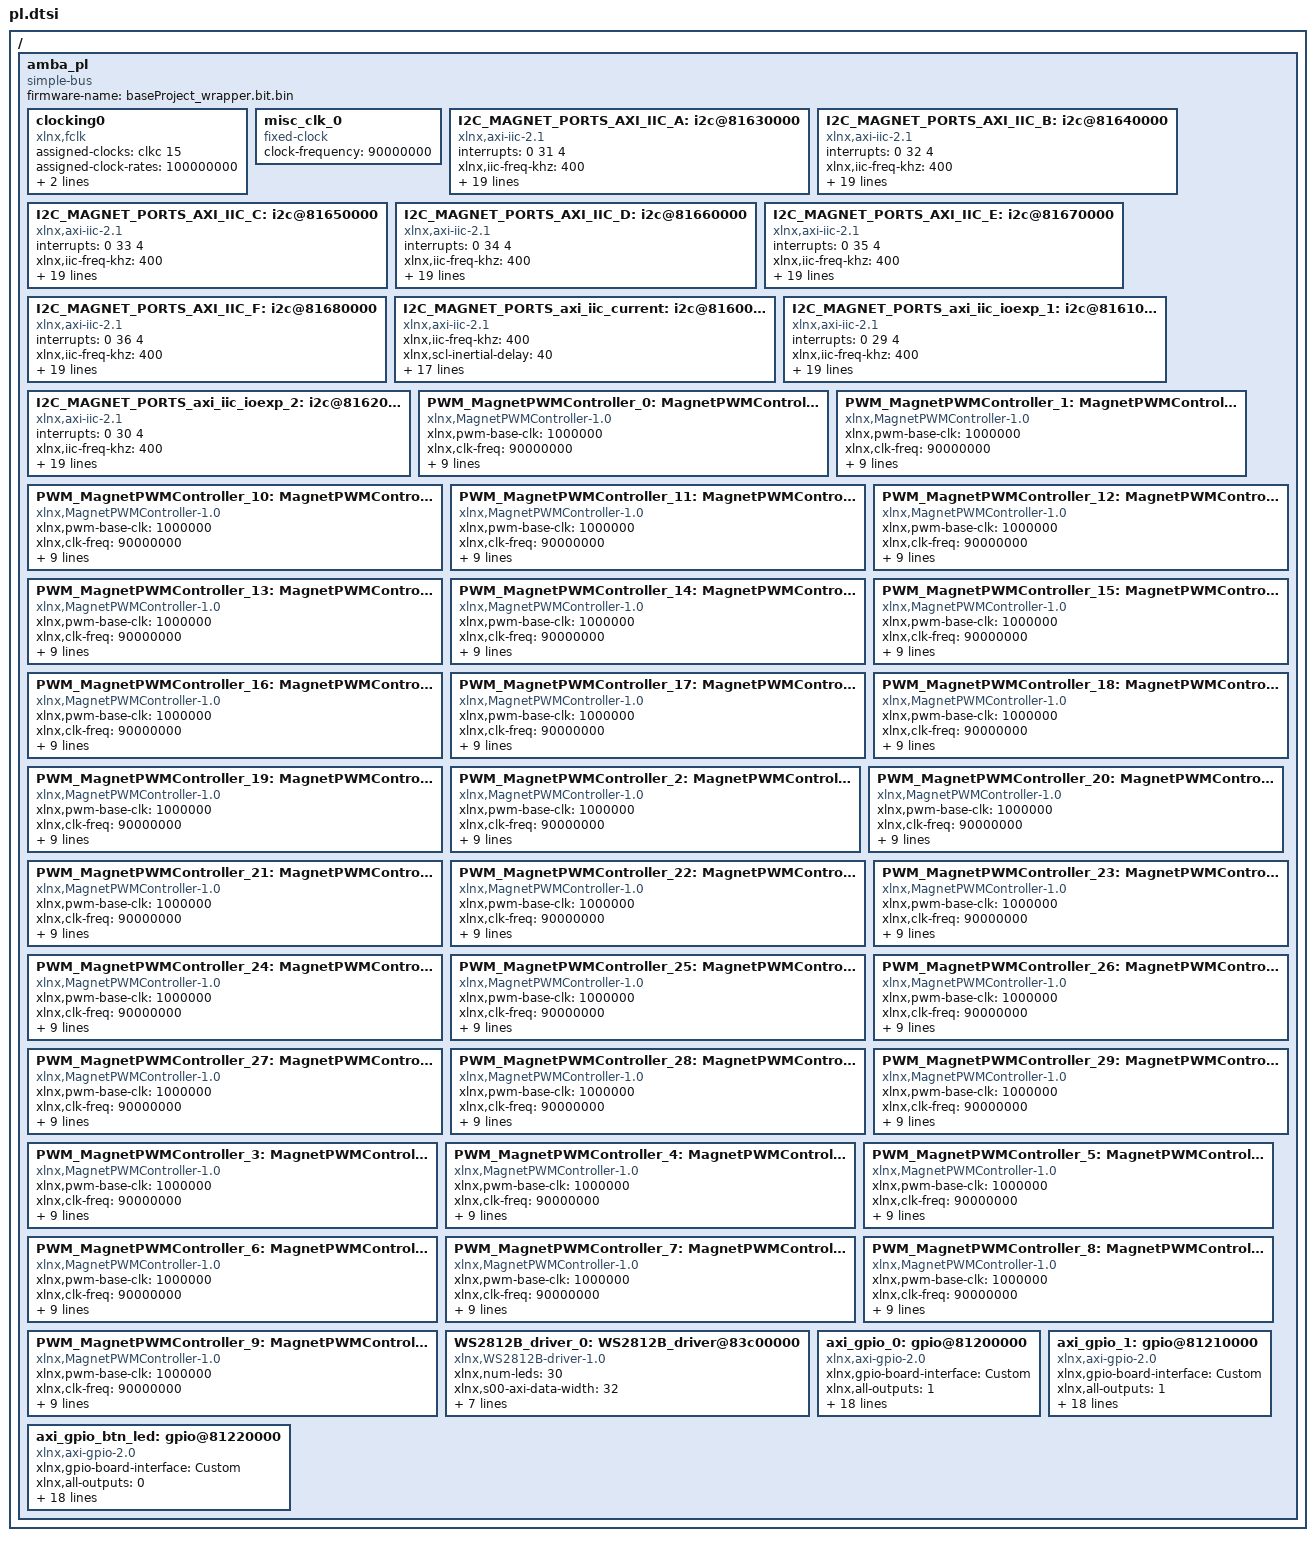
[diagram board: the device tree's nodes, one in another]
/ {
	amba_pl: amba_pl {
		ranges;
		compatible = "simple-bus";
		#address-cells = <1>;
		#size-cells = <1>;
		firmware-name = "baseProject_wrapper.bit.bin";
		clocking0: clocking0 {
			compatible = "xlnx,fclk";
			assigned-clocks = <&clkc 15>;
			assigned-clock-rates = <100000000>;
			#clock-cells = <0>;
			clock-output-names = "fabric_clk";
			clocks = <&clkc 15>;
		};
		misc_clk_0: misc_clk_0 {
			compatible = "fixed-clock";
			clock-frequency = <90000000>;
			#clock-cells = <0>;
		};
		I2C_MAGNET_PORTS_AXI_IIC_A: i2c@81630000 {
			interrupts = < 0 31 4 >;
			xlnx,iic-freq-khz = <400>;
			compatible = "xlnx,axi-iic-2.1" , "xlnx,xps-iic-2.00.a";
			xlnx,scl-inertial-delay = <40>;
			interrupt-parent = <&intc>;
			xlnx,ip-name = "axi_iic";
			xlnx,disable-setup-violation-check = <0>;
			reg = <0x81630000 0x10000>;
			clocks = <&misc_clk_0>;
			xlnx,gpo-width = <1>;
			xlnx,edk-iptype = "PERIPHERAL";
			xlnx,static-timing-reg-width = <0>;
			xlnx,sda-level = <1>;
			status = "okay";
			clock-names = "s_axi_aclk";
			xlnx,ten-bit-adr = <0>;
			xlnx,default-value = <0x0>;
			interrupt-names = "iic2intc_irpt";
			xlnx,iic-board-interface = "Custom";
			xlnx,timing-reg-width = <32>;
			xlnx,iic-freq = <400000>;
			xlnx,smbus-pmbus-host = <0>;
			xlnx,name = "I2C_MAGNET_PORTS_AXI_IIC_A";
			xlnx,axi-aclk-freq-mhz = <90>;
			xlnx,sda-inertial-delay = <40>;
		};
		I2C_MAGNET_PORTS_AXI_IIC_B: i2c@81640000 {
			interrupts = < 0 32 4 >;
			xlnx,iic-freq-khz = <400>;
			compatible = "xlnx,axi-iic-2.1" , "xlnx,xps-iic-2.00.a";
			xlnx,scl-inertial-delay = <40>;
			interrupt-parent = <&intc>;
			xlnx,ip-name = "axi_iic";
			xlnx,disable-setup-violation-check = <0>;
			reg = <0x81640000 0x10000>;
			clocks = <&misc_clk_0>;
			xlnx,gpo-width = <1>;
			xlnx,edk-iptype = "PERIPHERAL";
			xlnx,static-timing-reg-width = <0>;
			xlnx,sda-level = <1>;
			status = "okay";
			clock-names = "s_axi_aclk";
			xlnx,ten-bit-adr = <0>;
			xlnx,default-value = <0x0>;
			interrupt-names = "iic2intc_irpt";
			xlnx,iic-board-interface = "Custom";
			xlnx,timing-reg-width = <32>;
			xlnx,iic-freq = <400000>;
			xlnx,smbus-pmbus-host = <0>;
			xlnx,name = "I2C_MAGNET_PORTS_AXI_IIC_B";
			xlnx,axi-aclk-freq-mhz = <90>;
			xlnx,sda-inertial-delay = <40>;
		};
		I2C_MAGNET_PORTS_AXI_IIC_C: i2c@81650000 {
			interrupts = < 0 33 4 >;
			xlnx,iic-freq-khz = <400>;
			compatible = "xlnx,axi-iic-2.1" , "xlnx,xps-iic-2.00.a";
			xlnx,scl-inertial-delay = <40>;
			interrupt-parent = <&intc>;
			xlnx,ip-name = "axi_iic";
			xlnx,disable-setup-violation-check = <0>;
			reg = <0x81650000 0x10000>;
			clocks = <&misc_clk_0>;
			xlnx,gpo-width = <1>;
			xlnx,edk-iptype = "PERIPHERAL";
			xlnx,static-timing-reg-width = <0>;
			xlnx,sda-level = <1>;
			status = "okay";
			clock-names = "s_axi_aclk";
			xlnx,ten-bit-adr = <0>;
			xlnx,default-value = <0x0>;
			interrupt-names = "iic2intc_irpt";
			xlnx,iic-board-interface = "Custom";
			xlnx,timing-reg-width = <32>;
			xlnx,iic-freq = <400000>;
			xlnx,smbus-pmbus-host = <0>;
			xlnx,name = "I2C_MAGNET_PORTS_AXI_IIC_C";
			xlnx,axi-aclk-freq-mhz = <90>;
			xlnx,sda-inertial-delay = <40>;
		};
		I2C_MAGNET_PORTS_AXI_IIC_D: i2c@81660000 {
			interrupts = < 0 34 4 >;
			xlnx,iic-freq-khz = <400>;
			compatible = "xlnx,axi-iic-2.1" , "xlnx,xps-iic-2.00.a";
			xlnx,scl-inertial-delay = <40>;
			interrupt-parent = <&intc>;
			xlnx,ip-name = "axi_iic";
			xlnx,disable-setup-violation-check = <0>;
			reg = <0x81660000 0x10000>;
			clocks = <&misc_clk_0>;
			xlnx,gpo-width = <1>;
			xlnx,edk-iptype = "PERIPHERAL";
			xlnx,static-timing-reg-width = <0>;
			xlnx,sda-level = <1>;
			status = "okay";
			clock-names = "s_axi_aclk";
			xlnx,ten-bit-adr = <0>;
			xlnx,default-value = <0x0>;
			interrupt-names = "iic2intc_irpt";
			xlnx,iic-board-interface = "Custom";
			xlnx,timing-reg-width = <32>;
			xlnx,iic-freq = <400000>;
			xlnx,smbus-pmbus-host = <0>;
			xlnx,name = "I2C_MAGNET_PORTS_AXI_IIC_D";
			xlnx,axi-aclk-freq-mhz = <90>;
			xlnx,sda-inertial-delay = <40>;
		};
		I2C_MAGNET_PORTS_AXI_IIC_E: i2c@81670000 {
			interrupts = < 0 35 4 >;
			xlnx,iic-freq-khz = <400>;
			compatible = "xlnx,axi-iic-2.1" , "xlnx,xps-iic-2.00.a";
			xlnx,scl-inertial-delay = <40>;
			interrupt-parent = <&intc>;
			xlnx,ip-name = "axi_iic";
			xlnx,disable-setup-violation-check = <0>;
			reg = <0x81670000 0x10000>;
			clocks = <&misc_clk_0>;
			xlnx,gpo-width = <1>;
			xlnx,edk-iptype = "PERIPHERAL";
			xlnx,static-timing-reg-width = <0>;
			xlnx,sda-level = <1>;
			status = "okay";
			clock-names = "s_axi_aclk";
			xlnx,ten-bit-adr = <0>;
			xlnx,default-value = <0x0>;
			interrupt-names = "iic2intc_irpt";
			xlnx,iic-board-interface = "Custom";
			xlnx,timing-reg-width = <32>;
			xlnx,iic-freq = <400000>;
			xlnx,smbus-pmbus-host = <0>;
			xlnx,name = "I2C_MAGNET_PORTS_AXI_IIC_E";
			xlnx,axi-aclk-freq-mhz = <90>;
			xlnx,sda-inertial-delay = <40>;
		};
		I2C_MAGNET_PORTS_AXI_IIC_F: i2c@81680000 {
			interrupts = < 0 36 4 >;
			xlnx,iic-freq-khz = <400>;
			compatible = "xlnx,axi-iic-2.1" , "xlnx,xps-iic-2.00.a";
			xlnx,scl-inertial-delay = <40>;
			interrupt-parent = <&intc>;
			xlnx,ip-name = "axi_iic";
			xlnx,disable-setup-violation-check = <0>;
			reg = <0x81680000 0x10000>;
			clocks = <&misc_clk_0>;
			xlnx,gpo-width = <1>;
			xlnx,edk-iptype = "PERIPHERAL";
			xlnx,static-timing-reg-width = <0>;
			xlnx,sda-level = <1>;
			status = "okay";
			clock-names = "s_axi_aclk";
			xlnx,ten-bit-adr = <0>;
			xlnx,default-value = <0x0>;
			interrupt-names = "iic2intc_irpt";
			xlnx,iic-board-interface = "Custom";
			xlnx,timing-reg-width = <32>;
			xlnx,iic-freq = <400000>;
			xlnx,smbus-pmbus-host = <0>;
			xlnx,name = "I2C_MAGNET_PORTS_AXI_IIC_F";
			xlnx,axi-aclk-freq-mhz = <90>;
			xlnx,sda-inertial-delay = <40>;
		};
		I2C_MAGNET_PORTS_axi_iic_current: i2c@81600000 {
			xlnx,iic-freq-khz = <400>;
			compatible = "xlnx,axi-iic-2.1" , "xlnx,xps-iic-2.00.a";
			xlnx,scl-inertial-delay = <40>;
			xlnx,ip-name = "axi_iic";
			xlnx,disable-setup-violation-check = <0>;
			reg = <0x81600000 0x10000>;
			clocks = <&misc_clk_0>;
			xlnx,gpo-width = <1>;
			xlnx,edk-iptype = "PERIPHERAL";
			xlnx,static-timing-reg-width = <0>;
			xlnx,sda-level = <1>;
			status = "okay";
			clock-names = "s_axi_aclk";
			xlnx,ten-bit-adr = <0>;
			xlnx,default-value = <0x0>;
			xlnx,iic-board-interface = "Custom";
			xlnx,timing-reg-width = <32>;
			xlnx,iic-freq = <400000>;
			xlnx,smbus-pmbus-host = <0>;
			xlnx,name = "I2C_MAGNET_PORTS_axi_iic_current";
			xlnx,axi-aclk-freq-mhz = <90>;
			xlnx,sda-inertial-delay = <40>;
		};
		I2C_MAGNET_PORTS_axi_iic_ioexp_1: i2c@81610000 {
			interrupts = < 0 29 4 >;
			xlnx,iic-freq-khz = <400>;
			compatible = "xlnx,axi-iic-2.1" , "xlnx,xps-iic-2.00.a";
			xlnx,scl-inertial-delay = <40>;
			interrupt-parent = <&intc>;
			xlnx,ip-name = "axi_iic";
			xlnx,disable-setup-violation-check = <0>;
			reg = <0x81610000 0x10000>;
			clocks = <&misc_clk_0>;
			xlnx,gpo-width = <1>;
			xlnx,edk-iptype = "PERIPHERAL";
			xlnx,static-timing-reg-width = <0>;
			xlnx,sda-level = <1>;
			status = "okay";
			clock-names = "s_axi_aclk";
			xlnx,ten-bit-adr = <0>;
			xlnx,default-value = <0x0>;
			interrupt-names = "iic2intc_irpt";
			xlnx,iic-board-interface = "Custom";
			xlnx,timing-reg-width = <32>;
			xlnx,iic-freq = <400000>;
			xlnx,smbus-pmbus-host = <0>;
			xlnx,name = "I2C_MAGNET_PORTS_axi_iic_ioexp_1";
			xlnx,axi-aclk-freq-mhz = <90>;
			xlnx,sda-inertial-delay = <40>;
		};
		I2C_MAGNET_PORTS_axi_iic_ioexp_2: i2c@81620000 {
			interrupts = < 0 30 4 >;
			xlnx,iic-freq-khz = <400>;
			compatible = "xlnx,axi-iic-2.1" , "xlnx,xps-iic-2.00.a";
			xlnx,scl-inertial-delay = <40>;
			interrupt-parent = <&intc>;
			xlnx,ip-name = "axi_iic";
			xlnx,disable-setup-violation-check = <0>;
			reg = <0x81620000 0x10000>;
			clocks = <&misc_clk_0>;
			xlnx,gpo-width = <1>;
			xlnx,edk-iptype = "PERIPHERAL";
			xlnx,static-timing-reg-width = <0>;
			xlnx,sda-level = <1>;
			status = "okay";
			clock-names = "s_axi_aclk";
			xlnx,ten-bit-adr = <0>;
			xlnx,default-value = <0x0>;
			interrupt-names = "iic2intc_irpt";
			xlnx,iic-board-interface = "Custom";
			xlnx,timing-reg-width = <32>;
			xlnx,iic-freq = <400000>;
			xlnx,smbus-pmbus-host = <0>;
			xlnx,name = "I2C_MAGNET_PORTS_axi_iic_ioexp_2";
			xlnx,axi-aclk-freq-mhz = <90>;
			xlnx,sda-inertial-delay = <40>;
		};
		PWM_MagnetPWMController_0: MagnetPWMController@43c00000 {
			compatible = "xlnx,MagnetPWMController-1.0";
			xlnx,pwm-base-clk = <1000000>;
			xlnx,clk-freq = <90000000>;
			xlnx,s00-axi-data-width = <32>;
			xlnx,temp-histeresis = <10>;
			xlnx,ip-name = "MagnetPWMController";
			reg = <0x43c00000 0x10000>;
			clocks = <&misc_clk_0>, <&misc_clk_0>;
			xlnx,temp-limit = <90>;
			xlnx,edk-iptype = "PERIPHERAL";
			status = "okay";
			clock-names = "PL_CLK" , "s00_axi_aclk";
			xlnx,s00-axi-addr-width = <6>;
			xlnx,name = "PWM_MagnetPWMController_0";
		};
		PWM_MagnetPWMController_1: MagnetPWMController@43c10000 {
			compatible = "xlnx,MagnetPWMController-1.0";
			xlnx,pwm-base-clk = <1000000>;
			xlnx,clk-freq = <90000000>;
			xlnx,s00-axi-data-width = <32>;
			xlnx,temp-histeresis = <10>;
			xlnx,ip-name = "MagnetPWMController";
			reg = <0x43c10000 0x10000>;
			clocks = <&misc_clk_0>, <&misc_clk_0>;
			xlnx,temp-limit = <90>;
			xlnx,edk-iptype = "PERIPHERAL";
			status = "okay";
			clock-names = "PL_CLK" , "s00_axi_aclk";
			xlnx,s00-axi-addr-width = <6>;
			xlnx,name = "PWM_MagnetPWMController_1";
		};
		PWM_MagnetPWMController_10: MagnetPWMController@43ca0000 {
			compatible = "xlnx,MagnetPWMController-1.0";
			xlnx,pwm-base-clk = <1000000>;
			xlnx,clk-freq = <90000000>;
			xlnx,s00-axi-data-width = <32>;
			xlnx,temp-histeresis = <10>;
			xlnx,ip-name = "MagnetPWMController";
			reg = <0x43ca0000 0x10000>;
			clocks = <&misc_clk_0>, <&misc_clk_0>;
			xlnx,temp-limit = <90>;
			xlnx,edk-iptype = "PERIPHERAL";
			status = "okay";
			clock-names = "PL_CLK" , "s00_axi_aclk";
			xlnx,s00-axi-addr-width = <6>;
			xlnx,name = "PWM_MagnetPWMController_10";
		};
		PWM_MagnetPWMController_11: MagnetPWMController@43cb0000 {
			compatible = "xlnx,MagnetPWMController-1.0";
			xlnx,pwm-base-clk = <1000000>;
			xlnx,clk-freq = <90000000>;
			xlnx,s00-axi-data-width = <32>;
			xlnx,temp-histeresis = <10>;
			xlnx,ip-name = "MagnetPWMController";
			reg = <0x43cb0000 0x10000>;
			clocks = <&misc_clk_0>, <&misc_clk_0>;
			xlnx,temp-limit = <90>;
			xlnx,edk-iptype = "PERIPHERAL";
			status = "okay";
			clock-names = "PL_CLK" , "s00_axi_aclk";
			xlnx,s00-axi-addr-width = <6>;
			xlnx,name = "PWM_MagnetPWMController_11";
		};
		PWM_MagnetPWMController_12: MagnetPWMController@43cc0000 {
			compatible = "xlnx,MagnetPWMController-1.0";
			xlnx,pwm-base-clk = <1000000>;
			xlnx,clk-freq = <90000000>;
			xlnx,s00-axi-data-width = <32>;
			xlnx,temp-histeresis = <10>;
			xlnx,ip-name = "MagnetPWMController";
			reg = <0x43cc0000 0x10000>;
			clocks = <&misc_clk_0>, <&misc_clk_0>;
			xlnx,temp-limit = <90>;
			xlnx,edk-iptype = "PERIPHERAL";
			status = "okay";
			clock-names = "PL_CLK" , "s00_axi_aclk";
			xlnx,s00-axi-addr-width = <6>;
			xlnx,name = "PWM_MagnetPWMController_12";
		};
		PWM_MagnetPWMController_13: MagnetPWMController@43cd0000 {
			compatible = "xlnx,MagnetPWMController-1.0";
			xlnx,pwm-base-clk = <1000000>;
			xlnx,clk-freq = <90000000>;
			xlnx,s00-axi-data-width = <32>;
			xlnx,temp-histeresis = <10>;
			xlnx,ip-name = "MagnetPWMController";
			reg = <0x43cd0000 0x10000>;
			clocks = <&misc_clk_0>, <&misc_clk_0>;
			xlnx,temp-limit = <90>;
			xlnx,edk-iptype = "PERIPHERAL";
			status = "okay";
			clock-names = "PL_CLK" , "s00_axi_aclk";
			xlnx,s00-axi-addr-width = <6>;
			xlnx,name = "PWM_MagnetPWMController_13";
		};
		PWM_MagnetPWMController_14: MagnetPWMController@43ce0000 {
			compatible = "xlnx,MagnetPWMController-1.0";
			xlnx,pwm-base-clk = <1000000>;
			xlnx,clk-freq = <90000000>;
			xlnx,s00-axi-data-width = <32>;
			xlnx,temp-histeresis = <10>;
			xlnx,ip-name = "MagnetPWMController";
			reg = <0x43ce0000 0x10000>;
			clocks = <&misc_clk_0>, <&misc_clk_0>;
			xlnx,temp-limit = <90>;
			xlnx,edk-iptype = "PERIPHERAL";
			status = "okay";
			clock-names = "PL_CLK" , "s00_axi_aclk";
			xlnx,s00-axi-addr-width = <6>;
			xlnx,name = "PWM_MagnetPWMController_14";
		};
		PWM_MagnetPWMController_15: MagnetPWMController@43cf0000 {
			compatible = "xlnx,MagnetPWMController-1.0";
			xlnx,pwm-base-clk = <1000000>;
			xlnx,clk-freq = <90000000>;
			xlnx,s00-axi-data-width = <32>;
			xlnx,temp-histeresis = <10>;
			xlnx,ip-name = "MagnetPWMController";
			reg = <0x43cf0000 0x10000>;
			clocks = <&misc_clk_0>, <&misc_clk_0>;
			xlnx,temp-limit = <90>;
			xlnx,edk-iptype = "PERIPHERAL";
			status = "okay";
			clock-names = "PL_CLK" , "s00_axi_aclk";
			xlnx,s00-axi-addr-width = <6>;
			xlnx,name = "PWM_MagnetPWMController_15";
		};
		PWM_MagnetPWMController_16: MagnetPWMController@43d00000 {
			compatible = "xlnx,MagnetPWMController-1.0";
			xlnx,pwm-base-clk = <1000000>;
			xlnx,clk-freq = <90000000>;
			xlnx,s00-axi-data-width = <32>;
			xlnx,temp-histeresis = <10>;
			xlnx,ip-name = "MagnetPWMController";
			reg = <0x43d00000 0x10000>;
			clocks = <&misc_clk_0>, <&misc_clk_0>;
			xlnx,temp-limit = <90>;
			xlnx,edk-iptype = "PERIPHERAL";
			status = "okay";
			clock-names = "PL_CLK" , "s00_axi_aclk";
			xlnx,s00-axi-addr-width = <6>;
			xlnx,name = "PWM_MagnetPWMController_16";
		};
		PWM_MagnetPWMController_17: MagnetPWMController@43d10000 {
			compatible = "xlnx,MagnetPWMController-1.0";
			xlnx,pwm-base-clk = <1000000>;
			xlnx,clk-freq = <90000000>;
			xlnx,s00-axi-data-width = <32>;
			xlnx,temp-histeresis = <10>;
			xlnx,ip-name = "MagnetPWMController";
			reg = <0x43d10000 0x10000>;
			clocks = <&misc_clk_0>, <&misc_clk_0>;
			xlnx,temp-limit = <90>;
			xlnx,edk-iptype = "PERIPHERAL";
			status = "okay";
			clock-names = "PL_CLK" , "s00_axi_aclk";
			xlnx,s00-axi-addr-width = <6>;
			xlnx,name = "PWM_MagnetPWMController_17";
		};
		PWM_MagnetPWMController_18: MagnetPWMController@43d20000 {
			compatible = "xlnx,MagnetPWMController-1.0";
			xlnx,pwm-base-clk = <1000000>;
			xlnx,clk-freq = <90000000>;
			xlnx,s00-axi-data-width = <32>;
			xlnx,temp-histeresis = <10>;
			xlnx,ip-name = "MagnetPWMController";
			reg = <0x43d20000 0x10000>;
			clocks = <&misc_clk_0>, <&misc_clk_0>;
			xlnx,temp-limit = <90>;
			xlnx,edk-iptype = "PERIPHERAL";
			status = "okay";
			clock-names = "PL_CLK" , "s00_axi_aclk";
			xlnx,s00-axi-addr-width = <6>;
			xlnx,name = "PWM_MagnetPWMController_18";
		};
		PWM_MagnetPWMController_19: MagnetPWMController@43d30000 {
			compatible = "xlnx,MagnetPWMController-1.0";
			xlnx,pwm-base-clk = <1000000>;
			xlnx,clk-freq = <90000000>;
			xlnx,s00-axi-data-width = <32>;
			xlnx,temp-histeresis = <10>;
			xlnx,ip-name = "MagnetPWMController";
			reg = <0x43d30000 0x10000>;
			clocks = <&misc_clk_0>, <&misc_clk_0>;
			xlnx,temp-limit = <90>;
			xlnx,edk-iptype = "PERIPHERAL";
			status = "okay";
			clock-names = "PL_CLK" , "s00_axi_aclk";
			xlnx,s00-axi-addr-width = <6>;
			xlnx,name = "PWM_MagnetPWMController_19";
		};
		PWM_MagnetPWMController_2: MagnetPWMController@43c20000 {
			compatible = "xlnx,MagnetPWMController-1.0";
			xlnx,pwm-base-clk = <1000000>;
			xlnx,clk-freq = <90000000>;
			xlnx,s00-axi-data-width = <32>;
			xlnx,temp-histeresis = <10>;
			xlnx,ip-name = "MagnetPWMController";
			reg = <0x43c20000 0x10000>;
			clocks = <&misc_clk_0>, <&misc_clk_0>;
			xlnx,temp-limit = <90>;
			xlnx,edk-iptype = "PERIPHERAL";
			status = "okay";
			clock-names = "PL_CLK" , "s00_axi_aclk";
			xlnx,s00-axi-addr-width = <6>;
			xlnx,name = "PWM_MagnetPWMController_2";
		};
		PWM_MagnetPWMController_20: MagnetPWMController@43d40000 {
			compatible = "xlnx,MagnetPWMController-1.0";
			xlnx,pwm-base-clk = <1000000>;
			xlnx,clk-freq = <90000000>;
			xlnx,s00-axi-data-width = <32>;
			xlnx,temp-histeresis = <10>;
			xlnx,ip-name = "MagnetPWMController";
			reg = <0x43d40000 0x10000>;
			clocks = <&misc_clk_0>, <&misc_clk_0>;
			xlnx,temp-limit = <90>;
			xlnx,edk-iptype = "PERIPHERAL";
			status = "okay";
			clock-names = "PL_CLK" , "s00_axi_aclk";
			xlnx,s00-axi-addr-width = <6>;
			xlnx,name = "PWM_MagnetPWMController_20";
		};
		PWM_MagnetPWMController_21: MagnetPWMController@43d50000 {
			compatible = "xlnx,MagnetPWMController-1.0";
			xlnx,pwm-base-clk = <1000000>;
			xlnx,clk-freq = <90000000>;
			xlnx,s00-axi-data-width = <32>;
			xlnx,temp-histeresis = <10>;
			xlnx,ip-name = "MagnetPWMController";
			reg = <0x43d50000 0x10000>;
			clocks = <&misc_clk_0>, <&misc_clk_0>;
			xlnx,temp-limit = <90>;
			xlnx,edk-iptype = "PERIPHERAL";
			status = "okay";
			clock-names = "PL_CLK" , "s00_axi_aclk";
			xlnx,s00-axi-addr-width = <6>;
			xlnx,name = "PWM_MagnetPWMController_21";
		};
		PWM_MagnetPWMController_22: MagnetPWMController@43d60000 {
			compatible = "xlnx,MagnetPWMController-1.0";
			xlnx,pwm-base-clk = <1000000>;
			xlnx,clk-freq = <90000000>;
			xlnx,s00-axi-data-width = <32>;
			xlnx,temp-histeresis = <10>;
			xlnx,ip-name = "MagnetPWMController";
			reg = <0x43d60000 0x10000>;
			clocks = <&misc_clk_0>, <&misc_clk_0>;
			xlnx,temp-limit = <90>;
			xlnx,edk-iptype = "PERIPHERAL";
			status = "okay";
			clock-names = "PL_CLK" , "s00_axi_aclk";
			xlnx,s00-axi-addr-width = <6>;
			xlnx,name = "PWM_MagnetPWMController_22";
		};
		PWM_MagnetPWMController_23: MagnetPWMController@43d70000 {
			compatible = "xlnx,MagnetPWMController-1.0";
			xlnx,pwm-base-clk = <1000000>;
			xlnx,clk-freq = <90000000>;
			xlnx,s00-axi-data-width = <32>;
			xlnx,temp-histeresis = <10>;
			xlnx,ip-name = "MagnetPWMController";
			reg = <0x43d70000 0x10000>;
			clocks = <&misc_clk_0>, <&misc_clk_0>;
			xlnx,temp-limit = <90>;
			xlnx,edk-iptype = "PERIPHERAL";
			status = "okay";
			clock-names = "PL_CLK" , "s00_axi_aclk";
			xlnx,s00-axi-addr-width = <6>;
			xlnx,name = "PWM_MagnetPWMController_23";
		};
		PWM_MagnetPWMController_24: MagnetPWMController@43d80000 {
			compatible = "xlnx,MagnetPWMController-1.0";
			xlnx,pwm-base-clk = <1000000>;
			xlnx,clk-freq = <90000000>;
			xlnx,s00-axi-data-width = <32>;
			xlnx,temp-histeresis = <10>;
			xlnx,ip-name = "MagnetPWMController";
			reg = <0x43d80000 0x10000>;
			clocks = <&misc_clk_0>, <&misc_clk_0>;
			xlnx,temp-limit = <90>;
			xlnx,edk-iptype = "PERIPHERAL";
			status = "okay";
			clock-names = "PL_CLK" , "s00_axi_aclk";
			xlnx,s00-axi-addr-width = <6>;
			xlnx,name = "PWM_MagnetPWMController_24";
		};
		PWM_MagnetPWMController_25: MagnetPWMController@43d90000 {
			compatible = "xlnx,MagnetPWMController-1.0";
			xlnx,pwm-base-clk = <1000000>;
			xlnx,clk-freq = <90000000>;
			xlnx,s00-axi-data-width = <32>;
			xlnx,temp-histeresis = <10>;
			xlnx,ip-name = "MagnetPWMController";
			reg = <0x43d90000 0x10000>;
			clocks = <&misc_clk_0>, <&misc_clk_0>;
			xlnx,temp-limit = <90>;
			xlnx,edk-iptype = "PERIPHERAL";
			status = "okay";
			clock-names = "PL_CLK" , "s00_axi_aclk";
			xlnx,s00-axi-addr-width = <6>;
			xlnx,name = "PWM_MagnetPWMController_25";
		};
		PWM_MagnetPWMController_26: MagnetPWMController@43da0000 {
			compatible = "xlnx,MagnetPWMController-1.0";
			xlnx,pwm-base-clk = <1000000>;
			xlnx,clk-freq = <90000000>;
			xlnx,s00-axi-data-width = <32>;
			xlnx,temp-histeresis = <10>;
			xlnx,ip-name = "MagnetPWMController";
			reg = <0x43da0000 0x10000>;
			clocks = <&misc_clk_0>, <&misc_clk_0>;
			xlnx,temp-limit = <90>;
			xlnx,edk-iptype = "PERIPHERAL";
			status = "okay";
			clock-names = "PL_CLK" , "s00_axi_aclk";
			xlnx,s00-axi-addr-width = <6>;
			xlnx,name = "PWM_MagnetPWMController_26";
		};
		PWM_MagnetPWMController_27: MagnetPWMController@43db0000 {
			compatible = "xlnx,MagnetPWMController-1.0";
			xlnx,pwm-base-clk = <1000000>;
			xlnx,clk-freq = <90000000>;
			xlnx,s00-axi-data-width = <32>;
			xlnx,temp-histeresis = <10>;
			xlnx,ip-name = "MagnetPWMController";
			reg = <0x43db0000 0x10000>;
			clocks = <&misc_clk_0>, <&misc_clk_0>;
			xlnx,temp-limit = <90>;
			xlnx,edk-iptype = "PERIPHERAL";
			status = "okay";
			clock-names = "PL_CLK" , "s00_axi_aclk";
			xlnx,s00-axi-addr-width = <6>;
			xlnx,name = "PWM_MagnetPWMController_27";
		};
		PWM_MagnetPWMController_28: MagnetPWMController@43dc0000 {
			compatible = "xlnx,MagnetPWMController-1.0";
			xlnx,pwm-base-clk = <1000000>;
			xlnx,clk-freq = <90000000>;
			xlnx,s00-axi-data-width = <32>;
			xlnx,temp-histeresis = <10>;
			xlnx,ip-name = "MagnetPWMController";
			reg = <0x43dc0000 0x10000>;
			clocks = <&misc_clk_0>, <&misc_clk_0>;
			xlnx,temp-limit = <90>;
			xlnx,edk-iptype = "PERIPHERAL";
			status = "okay";
			clock-names = "PL_CLK" , "s00_axi_aclk";
			xlnx,s00-axi-addr-width = <6>;
			xlnx,name = "PWM_MagnetPWMController_28";
		};
		PWM_MagnetPWMController_29: MagnetPWMController@43dd0000 {
			compatible = "xlnx,MagnetPWMController-1.0";
			xlnx,pwm-base-clk = <1000000>;
			xlnx,clk-freq = <90000000>;
			xlnx,s00-axi-data-width = <32>;
			xlnx,temp-histeresis = <10>;
			xlnx,ip-name = "MagnetPWMController";
			reg = <0x43dd0000 0x10000>;
			clocks = <&misc_clk_0>, <&misc_clk_0>;
			xlnx,temp-limit = <90>;
			xlnx,edk-iptype = "PERIPHERAL";
			status = "okay";
			clock-names = "PL_CLK" , "s00_axi_aclk";
			xlnx,s00-axi-addr-width = <6>;
			xlnx,name = "PWM_MagnetPWMController_29";
		};
		PWM_MagnetPWMController_3: MagnetPWMController@43c30000 {
			compatible = "xlnx,MagnetPWMController-1.0";
			xlnx,pwm-base-clk = <1000000>;
			xlnx,clk-freq = <90000000>;
			xlnx,s00-axi-data-width = <32>;
			xlnx,temp-histeresis = <10>;
			xlnx,ip-name = "MagnetPWMController";
			reg = <0x43c30000 0x10000>;
			clocks = <&misc_clk_0>, <&misc_clk_0>;
			xlnx,temp-limit = <90>;
			xlnx,edk-iptype = "PERIPHERAL";
			status = "okay";
			clock-names = "PL_CLK" , "s00_axi_aclk";
			xlnx,s00-axi-addr-width = <6>;
			xlnx,name = "PWM_MagnetPWMController_3";
		};
		PWM_MagnetPWMController_4: MagnetPWMController@43c40000 {
			compatible = "xlnx,MagnetPWMController-1.0";
			xlnx,pwm-base-clk = <1000000>;
			xlnx,clk-freq = <90000000>;
			xlnx,s00-axi-data-width = <32>;
			xlnx,temp-histeresis = <10>;
			xlnx,ip-name = "MagnetPWMController";
			reg = <0x43c40000 0x10000>;
			clocks = <&misc_clk_0>, <&misc_clk_0>;
			xlnx,temp-limit = <90>;
			xlnx,edk-iptype = "PERIPHERAL";
			status = "okay";
			clock-names = "PL_CLK" , "s00_axi_aclk";
			xlnx,s00-axi-addr-width = <6>;
			xlnx,name = "PWM_MagnetPWMController_4";
		};
		PWM_MagnetPWMController_5: MagnetPWMController@43c50000 {
			compatible = "xlnx,MagnetPWMController-1.0";
			xlnx,pwm-base-clk = <1000000>;
			xlnx,clk-freq = <90000000>;
			xlnx,s00-axi-data-width = <32>;
			xlnx,temp-histeresis = <10>;
			xlnx,ip-name = "MagnetPWMController";
			reg = <0x43c50000 0x10000>;
			clocks = <&misc_clk_0>, <&misc_clk_0>;
			xlnx,temp-limit = <90>;
			xlnx,edk-iptype = "PERIPHERAL";
			status = "okay";
			clock-names = "PL_CLK" , "s00_axi_aclk";
			xlnx,s00-axi-addr-width = <6>;
			xlnx,name = "PWM_MagnetPWMController_5";
		};
		PWM_MagnetPWMController_6: MagnetPWMController@43c60000 {
			compatible = "xlnx,MagnetPWMController-1.0";
			xlnx,pwm-base-clk = <1000000>;
			xlnx,clk-freq = <90000000>;
			xlnx,s00-axi-data-width = <32>;
			xlnx,temp-histeresis = <10>;
			xlnx,ip-name = "MagnetPWMController";
			reg = <0x43c60000 0x10000>;
			clocks = <&misc_clk_0>, <&misc_clk_0>;
			xlnx,temp-limit = <90>;
			xlnx,edk-iptype = "PERIPHERAL";
			status = "okay";
			clock-names = "PL_CLK" , "s00_axi_aclk";
			xlnx,s00-axi-addr-width = <6>;
			xlnx,name = "PWM_MagnetPWMController_6";
		};
		PWM_MagnetPWMController_7: MagnetPWMController@43c70000 {
			compatible = "xlnx,MagnetPWMController-1.0";
			xlnx,pwm-base-clk = <1000000>;
			xlnx,clk-freq = <90000000>;
			xlnx,s00-axi-data-width = <32>;
			xlnx,temp-histeresis = <10>;
			xlnx,ip-name = "MagnetPWMController";
			reg = <0x43c70000 0x10000>;
			clocks = <&misc_clk_0>, <&misc_clk_0>;
			xlnx,temp-limit = <90>;
			xlnx,edk-iptype = "PERIPHERAL";
			status = "okay";
			clock-names = "PL_CLK" , "s00_axi_aclk";
			xlnx,s00-axi-addr-width = <6>;
			xlnx,name = "PWM_MagnetPWMController_7";
		};
		PWM_MagnetPWMController_8: MagnetPWMController@43c80000 {
			compatible = "xlnx,MagnetPWMController-1.0";
			xlnx,pwm-base-clk = <1000000>;
			xlnx,clk-freq = <90000000>;
			xlnx,s00-axi-data-width = <32>;
			xlnx,temp-histeresis = <10>;
			xlnx,ip-name = "MagnetPWMController";
			reg = <0x43c80000 0x10000>;
			clocks = <&misc_clk_0>, <&misc_clk_0>;
			xlnx,temp-limit = <90>;
			xlnx,edk-iptype = "PERIPHERAL";
			status = "okay";
			clock-names = "PL_CLK" , "s00_axi_aclk";
			xlnx,s00-axi-addr-width = <6>;
			xlnx,name = "PWM_MagnetPWMController_8";
		};
		PWM_MagnetPWMController_9: MagnetPWMController@43c90000 {
			compatible = "xlnx,MagnetPWMController-1.0";
			xlnx,pwm-base-clk = <1000000>;
			xlnx,clk-freq = <90000000>;
			xlnx,s00-axi-data-width = <32>;
			xlnx,temp-histeresis = <10>;
			xlnx,ip-name = "MagnetPWMController";
			reg = <0x43c90000 0x10000>;
			clocks = <&misc_clk_0>, <&misc_clk_0>;
			xlnx,temp-limit = <90>;
			xlnx,edk-iptype = "PERIPHERAL";
			status = "okay";
			clock-names = "PL_CLK" , "s00_axi_aclk";
			xlnx,s00-axi-addr-width = <6>;
			xlnx,name = "PWM_MagnetPWMController_9";
		};
		WS2812B_driver_0: WS2812B_driver@83c00000 {
			compatible = "xlnx,WS2812B-driver-1.0";
			xlnx,num-leds = <30>;
			xlnx,s00-axi-data-width = <32>;
			xlnx,ip-name = "WS2812B_driver";
			reg = <0x83c00000 0x10000>;
			clocks = <&misc_clk_0>, <&misc_clk_0>;
			xlnx,edk-iptype = "PERIPHERAL";
			status = "okay";
			xlnx,system-clock = <90000000>;
			xlnx,s00-axi-addr-width = <4>;
			clock-names = "s00_axi_aclk" , "sys_clk";
			xlnx,name = "WS2812B_driver_0";
		};
		axi_gpio_0: gpio@81200000 {
			xlnx,gpio-board-interface = "Custom";
			compatible = "xlnx,axi-gpio-2.0" , "xlnx,xps-gpio-1.00.a";
			xlnx,all-outputs = <1>;
			#gpio-cells = <2>;
			xlnx,gpio-width = <1>;
			xlnx,dout-default = <0x0>;
			xlnx,is-dual = <0>;
			xlnx,ip-name = "axi_gpio";
			xlnx,tri-default-2 = <0xffffffff>;
			reg = <0x81200000 0x10000>;
			xlnx,all-inputs-2 = <0>;
			clocks = <&misc_clk_0>;
			xlnx,all-outputs-2 = <0>;
			gpio-controller;
			xlnx,interrupt-present = <0>;
			xlnx,gpio2-board-interface = "Custom";
			xlnx,edk-iptype = "PERIPHERAL";
			xlnx,dout-default-2 = <0x0>;
			status = "okay";
			xlnx,gpio2-width = <32>;
			clock-names = "s_axi_aclk";
			xlnx,tri-default = <0xffffffff>;
			xlnx,name = "axi_gpio_0";
			xlnx,all-inputs = <0>;
		};
		axi_gpio_1: gpio@81210000 {
			xlnx,gpio-board-interface = "Custom";
			compatible = "xlnx,axi-gpio-2.0" , "xlnx,xps-gpio-1.00.a";
			xlnx,all-outputs = <1>;
			#gpio-cells = <2>;
			xlnx,gpio-width = <1>;
			xlnx,dout-default = <0x0>;
			xlnx,is-dual = <0>;
			xlnx,ip-name = "axi_gpio";
			xlnx,tri-default-2 = <0xffffffff>;
			reg = <0x81210000 0x10000>;
			xlnx,all-inputs-2 = <0>;
			clocks = <&misc_clk_0>;
			xlnx,all-outputs-2 = <0>;
			gpio-controller;
			xlnx,interrupt-present = <0>;
			xlnx,gpio2-board-interface = "Custom";
			xlnx,edk-iptype = "PERIPHERAL";
			xlnx,dout-default-2 = <0x0>;
			status = "okay";
			xlnx,gpio2-width = <32>;
			clock-names = "s_axi_aclk";
			xlnx,tri-default = <0xffffffff>;
			xlnx,name = "axi_gpio_1";
			xlnx,all-inputs = <0>;
		};
		axi_gpio_btn_led: gpio@81220000 {
			xlnx,gpio-board-interface = "Custom";
			compatible = "xlnx,axi-gpio-2.0" , "xlnx,xps-gpio-1.00.a";
			xlnx,all-outputs = <0>;
			#gpio-cells = <2>;
			xlnx,gpio-width = <5>;
			xlnx,dout-default = <0x0>;
			xlnx,is-dual = <0>;
			xlnx,ip-name = "axi_gpio";
			xlnx,tri-default-2 = <0xffffffff>;
			reg = <0x81220000 0x10000>;
			xlnx,all-inputs-2 = <0>;
			clocks = <&misc_clk_0>;
			xlnx,all-outputs-2 = <0>;
			gpio-controller;
			xlnx,interrupt-present = <0>;
			xlnx,gpio2-board-interface = "Custom";
			xlnx,edk-iptype = "PERIPHERAL";
			xlnx,dout-default-2 = <0x0>;
			status = "okay";
			xlnx,gpio2-width = <32>;
			clock-names = "s_axi_aclk";
			xlnx,tri-default = <0xffffffff>;
			xlnx,name = "axi_gpio_btn_led";
			xlnx,all-inputs = <0>;
		};
	};
};
